# STM32G534 register map
File version: 2.0.0
CPU: CM33 r0p4, little endian, MPU, FPU, 4 interrupt priority bits
Registers are 32-bit, read-write, reset 0x0 unless marked. A register's access mark holds for its fields unless they carry their own. Offsets are from the block's base; [hi:lo] are bit positions.

## PKA — PKA register blank and RAM
Base 0x46008000
Same registers: PKA_S 0x56008000
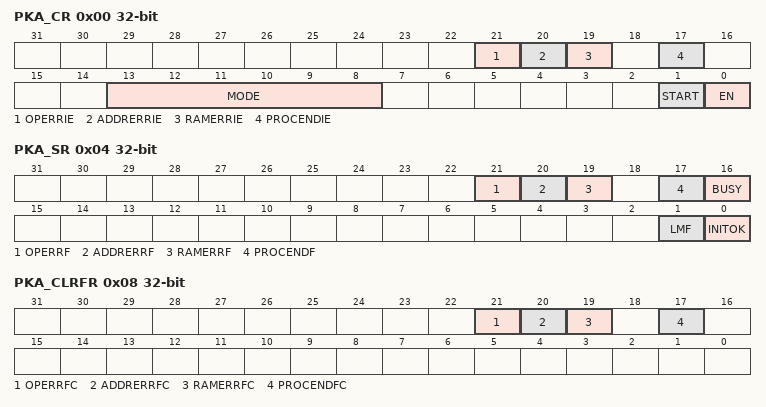
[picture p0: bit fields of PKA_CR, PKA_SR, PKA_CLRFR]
0x00 PKA_CR — PKA control register
  [21] OPERRIE — Operation error interrupt enable
    0=No interrupt is generated when OPERRF flag is set in PKA_SR; 1=An interrupt is generated when OPERRF flag is set in PKA_SR
  [20] ADDRERRIE — Address error interrupt enable
    0=No interrupt is generated when ADDRERRF flag is set in PKA_SR; 1=An interrupt is generated when ADDRERRF flag is set in PKA_SR
  [19] RAMERRIE — RAM error interrupt enable
    0=No interrupt is generated when RAMERRF flag is set in PKA_SR; 1=An interrupt is generated when RAMERRF flag is set in PKA_SR
  [17] PROCENDIE — End of operation interrupt enable
    0=No interrupt is generated when PROCENDF flag is set in PKA_SR; 1=An interrupt is generated when PROCENDF flag is set in PKA_SR
  [13:8] MODE — PKA operation code
    0=Montgomery parameter computation then modular exponentiation; 1=Montgomery parameter computation only; 2=Modular exponentiation only (Montgomery parameter must be loaded first); 32=Montgomery parameter computation then ECC scalar multiplication; 36=ECDSA sign; 38=ECDSA verification; 40=Point on elliptic curve Fp check; 7=RSA CRT exponentiation; 8=Modular inversion; 9=Arithmetic addition; 10=Arithmetic subtraction; 11=Arithmetic multiplication; 12=Arithmetic comparison; 13=Modular reduction; 14=Modular addition; 15=Modular subtraction; 16=Montgomery multiplication; 35=ECC complete addition; 39=ECC double base ladder; 47=ECC projective to affine
  [1] START — start the operation
  [0] EN — PKA enable
    0=Disable PKA; 1=Enable PKA
0x04 PKA_SR ro — PKA status register
  [21] OPERRF — Operation error flag
    0=No event error; 1=An illegal or unknown operation has been selected in PKA_CR register
  [20] ADDRERRF — Address error flag
    0=No address error; 1=Address access is out of range (unmapped address)
  [19] RAMERRF — PKA RAM error flag
    0=No PKA RAM access error; 1=An AHB access to the PKA RAM occurred while the PKA core was computing and using its internal RAM (AHB PKA_RAM access are not allowed while PKA operation is in progress)
  [17] PROCENDF — PKA end of operation flag
    0=Operation in progress; 1=PKA operation is completed. This flag is set when the BUSY bit is deasserted.
  [16] BUSY — Busy flag
    0=No operation is in progress (default); 1=An operation is in progress
  [1] LMF — Limited mode flag
    0=All values documented in MODE[5:0] bit field can be used; 1=Only ECDSA verification (MODE[5:0] = 0x26) is supported by the PKA
  [0] INITOK — PKA initialization OK
    0=PKA is not initialized correctly. START bit cannot be set.; 1=PKA is initialized correctly and can be used normally
0x08 PKA_CLRFR wo — PKA clear flag register
  [21] OPERRFC — Clear operation error flag
    0=No action; 1=Clear the OPERRF flag in PKA_SR
  [20] ADDRERRFC — Clear address error flag
    0=No action; 1=Clear the ADDRERRF flag in PKA_SR
  [19] RAMERRFC — Clear PKA RAM error flag
    0=No action; 1=Clear the RAMERRF flag in PKA_SR
  [17] PROCENDFC — Clear PKA end of operation flag
    0=No action; 1=Clear the PROCENDF flag in PKA_SR

## TIM6 — TIM address block description
Base 0x40001000
Same registers: TIM6_S 0x50001000
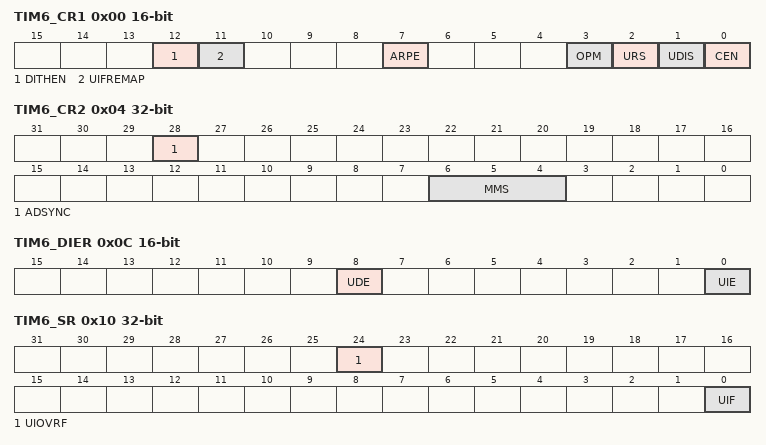
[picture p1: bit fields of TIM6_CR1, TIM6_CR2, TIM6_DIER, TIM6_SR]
0x00 TIM6_CR1 16-bit — TIM6 control register 1
  [12] DITHEN — Dithering enable
    0=Dithering disabled; 1=Dithering enabled
  [11] UIFREMAP — UIF status bit remapping
    0=No remapping; 1=Remapping enabled
  [7] ARPE — Auto-reload preload enable
    0=TIMx_ARR register is not buffered; 1=TIMx_ARR register is buffered
  [3] OPM — One-pulse mode
    0=Counter is not stopped at update event; 1=Counter stops counting at the next update event (clearing the CEN bit)
  [2] URS — Update request source
    0=Any of the following events generates an update interrupt or DMA request if enabled; 1=Only counter overflow/underflow generates an update interrupt or DMA request if enabled
  [1] UDIS — Update disable
    0=UEV enabled; 1=UEV disabled
  [0] CEN — Counter enable
    0=Counter disabled; 1=Counter enabled
0x04 TIM6_CR2 — TIM6 control register 2
  [28] ADSYNC — ADC synchronization
    0=The timer operates independently from the ADC; 1=The timer operation is synchronized with the ADC clock to provide jitter-free sampling point
  [6:4] MMS — Master mode selection
    0=Reset - the UG bit from the TIMx_EGR register is used as a trigger output (tim_trgo); 1=Enable - the Counter enable signal, tim_cnt_en, is used as a trigger output (tim_trgo); 2=Update - The update event is selected as a trigger output (tim_trgo)
0x0C TIM6_DIER 16-bit — TIM6 DMA/Interrupt enable register
  [8] UDE — Update DMA request enable
    0=Update DMA request disabled; 1=Update DMA request enabled
  [0] UIE — Update interrupt enable
    0=Update interrupt disabled; 1=Update interrupt enabled
0x10 TIM6_SR — TIM6 status register
  [24] UIOVRF — Update Interrupt Overrun flag
    0=No Update Interrupt Overrun; 1=Update Interrupt Overrun
  [0] UIF — Update interrupt flag
    0=No update occurred; 1=Update interrupt pending
0x14 TIM6_EGR 16-bit wo — TIM6 event generation register
  [0] UG — Update generation
    0=No action; 1=Re-initializes the timer counter and generates an update of the registers
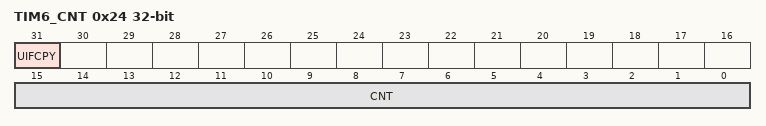
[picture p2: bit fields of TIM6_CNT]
0x24 TIM6_CNT — TIM6 counter
  [31] UIFCPY ro — UIF copy
  [15:0] CNT — Counter value
0x28 TIM6_PSC 16-bit — TIM6 prescaler
  [15:0] PSC — Prescaler value
0x2C TIM6_ARR reset 0xFFFF — TIM6 autoreload register
  [19:0] ARR — Auto-reload value

## TIM7 — TIM address block description
Base 0x40001400
Same registers: TIM7_S 0x50001400
Registers as TIM6 (with TIM6 read as TIM7).

## TIM26 — TIM address block description
Base 0x44000C00
Same registers: TIM26_S 0x54000C00
Registers as TIM6 (with TIM6 read as TIM26).

## TIM27 — TIM address block description
Base 0x44001000
Same registers: TIM27_S 0x54001000
Registers as TIM6 (with TIM6 read as TIM27).

## VREFBUF — VREFBUF address block description
Base 0x44007400
Same registers: VREFBUF_S 0x54007400
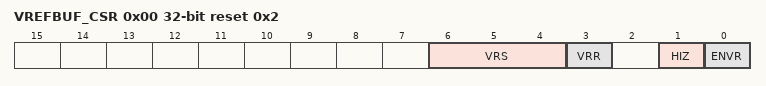
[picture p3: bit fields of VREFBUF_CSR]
0x00 VREFBUF_CSR reset 0x2 — VREFBUF control and status register
  [6:4] VRS — Voltage reference scale
  [3] VRR ro — Voltage reference buffer ready
    0=the voltage reference buffer output is not ready; 1=the voltage reference buffer output reached the requested level
  [1] HIZ — High impedance mode
    0=Vless thansub>REF+less than/sub> pin is internally connected to the voltage reference buffer output; 1=Vless thansub>REF+less than/sub> pin is high impedance
  [0] ENVR — Voltage reference buffer mode enable
    0=Internal voltage reference mode disable (external voltage reference mode); 1=Internal voltage reference mode (reference buffer enable or hold mode) enable
0x04 VREFBUF_CCR (reset mask 0xFFFFFF00) — VREFBUF calibration control register
  [5:0] TRIM — Trimming code

## WWDG — WWDG address block description
Base 0x40003000
Same registers: WWDG_S 0x50003000
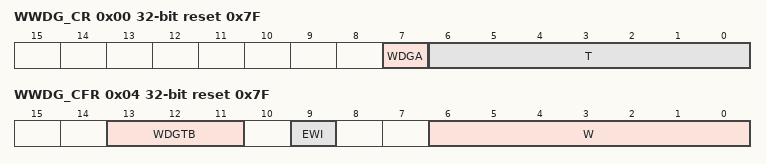
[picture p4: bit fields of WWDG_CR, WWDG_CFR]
0x00 WWDG_CR reset 0x7F — WWDG control register
  [7] WDGA — Activation bit
    0=Watchdog disabled; 1=Watchdog enabled
  [6:0] T — 7-bit counter (MSB to LSB)
0x04 WWDG_CFR reset 0x7F — WWDG configuration register
  [13:11] WDGTB — Timer base
    0=CK counter clock (PCLK div 4096) div 1; 1=CK counter clock (PCLK div 4096) div 2; 2=CK counter clock (PCLK div 4096) div 4; 3=CK counter clock (PCLK div 4096) div 8; 4=CK counter clock (PCLK div 4096) div 16; 5=CK counter clock (PCLK div 4096) div 32; 6=CK counter clock (PCLK div 4096) div 64; 7=CK counter clock (PCLK div 4096) div 128
  [9] EWI — Early wake-up interrupt enable
  [6:0] W — 7-bit window value
0x08 WWDG_SR — WWDG status register
  [0] EWIF — Early wake-up interrupt flag
